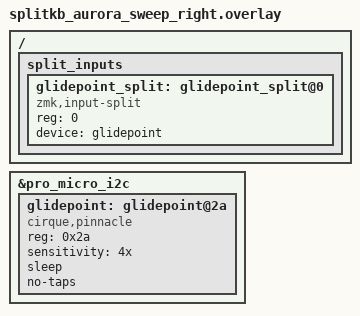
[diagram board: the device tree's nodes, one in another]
&pro_micro_i2c {
    status = "okay";
    glidepoint: glidepoint@2a {
        compatible = "cirque,pinnacle";
        reg = <0x2a>;
        status = "okay";
        sensitivity = "4x";
        sleep;
        no-taps;
    };
};

/ {
    split_inputs {
        #address-cells = <1>;
        #size-cells = <0>;
        glidepoint_split: glidepoint_split@0 {
            compatible = "zmk,input-split";
            reg = <0>;
            device = <&glidepoint>;
        };
    };
};
